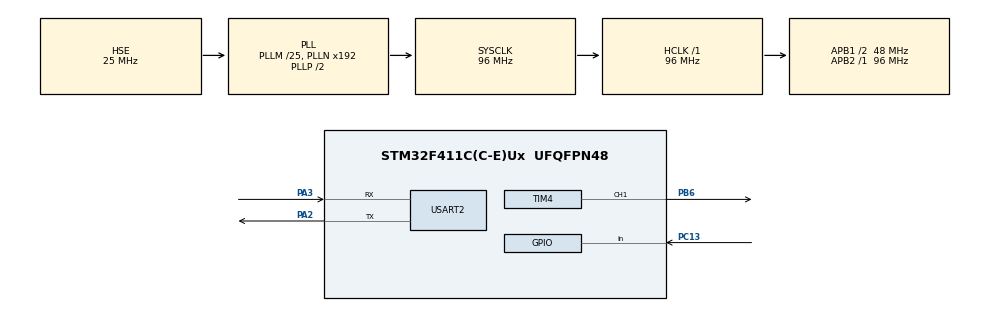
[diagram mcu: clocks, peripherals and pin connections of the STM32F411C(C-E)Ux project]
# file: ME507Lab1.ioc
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Mcu.Family=STM32F4
Mcu.Name=STM32F411C(C-E)Ux
Mcu.Package=UFQFPN48
NVIC.PriorityGroup=NVIC_PRIORITYGROUP_4
NVIC.TIM4_IRQn=true\:0\:0\:false\:false\:true\:true\:true\:true
PA13.Mode=Trace_Asynchronous_SW
PA13.Signal=SYS_JTMS-SWDIO
PA14.Mode=Trace_Asynchronous_SW
PA14.Signal=SYS_JTCK-SWCLK
PA2.Mode=Asynchronous
PA2.Signal=USART2_TX
PA3.Mode=Asynchronous
PA3.Signal=USART2_RX
PB3.Mode=Trace_Asynchronous_SW
PB3.Signal=SYS_JTDO-SWO
PB6.Signal=S_TIM4_CH1
PC13-ANTI_TAMP.Signal=GPIO_Input
PH0\ -\ OSC_IN.Mode=HSE-External-Oscillator
PH0\ -\ OSC_IN.Signal=RCC_OSC_IN
PH1\ -\ OSC_OUT.Mode=HSE-External-Oscillator
PH1\ -\ OSC_OUT.Signal=RCC_OSC_OUT
ProjectManager.HeapSize=0x200
ProjectManager.StackSize=0x400
ProjectManager.TargetToolchain=STM32CubeIDE
RCC.48MHZClocksFreq_Value=48000000
RCC.AHBFreq_Value=96000000
RCC.APB1CLKDivider=RCC_HCLK_DIV2
RCC.APB1Freq_Value=48000000
RCC.APB1TimFreq_Value=96000000
RCC.APB2Freq_Value=96000000
RCC.APB2TimFreq_Value=96000000
RCC.CortexFreq_Value=96000000
RCC.HCLKFreq_Value=96000000
RCC.HSE_VALUE=25000000
RCC.HSI_VALUE=16000000
RCC.LSE_VALUE=32768
RCC.PLLM=25
RCC.PLLSourceVirtual=RCC_PLLSOURCE_HSE
RCC.SYSCLKFreq_VALUE=96000000
RCC.SYSCLKSource=RCC_SYSCLKSOURCE_PLLCLK
RCC.VCOOutputFreq_Value=192000000
SH.S_TIM4_CH1.0=TIM4_CH1,PWM Generation1 CH1
TIM4.Channel-PWM\ Generation1\ CH1=TIM_CHANNEL_1
TIM4.OCPolarity_1=TIM_OCPOLARITY_LOW
TIM4.Period=63999
TIM4.Prescaler=749
TIM4.Pulse-PWM\ Generation1\ CH1=25600
TIM4.TIM_MasterOutputTrigger=TIM_TRGO_OC1
USART2.VirtualMode=VM_ASYNC
VP_TIM5_VS_ClockSourceITR.Mode=TriggerSource_ITR2
VP_TIM5_VS_ControllerModeClock.Mode=Clock Mode
board=custom

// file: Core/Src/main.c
/* USER CODE BEGIN Header */
/**
  ******************************************************************************
  * @file           : main.c
  * @brief          : Main program body
  ******************************************************************************
  * @attention
  *
  * Copyright (c) 2026 STMicroelectronics.
  * All rights reserved.
  *
  * This software is licensed under terms that can be found in the LICENSE file
  * in the root directory of this software component.
  * If no LICENSE file comes with this software, it is provided AS-IS.
  *
  ******************************************************************************
  */
/* USER CODE END Header */
#include "main.h"

/* USER CODE BEGIN Includes */
#include <stdio.h>
/* USER CODE END Includes */

TIM_HandleTypeDef htim4;
TIM_HandleTypeDef htim5;

UART_HandleTypeDef huart2;

/* USER CODE BEGIN PV */
uint16_t pulse_width = 25600;
char buffer [100];
int buffer_len;
/* USER CODE END PV */

void SystemClock_Config(void);
static void MX_GPIO_Init(void);
static void MX_USART2_UART_Init(void);
static void MX_TIM4_Init(void);
static void MX_TIM5_Init(void);

int main(void)
{

  /* MCU Configuration--------------------------------------------------------*/

  /* Reset of all peripherals, Initializes the Flash interface and the Systick. */
  HAL_Init();

  /* Configure the system clock */
  SystemClock_Config();

  /* Initialize all configured peripherals */
  MX_GPIO_Init();
  MX_USART2_UART_Init();
  MX_TIM4_Init();
  MX_TIM5_Init();
  /* USER CODE BEGIN 2 */
  HAL_TIM_PWM_Start_IT(&htim4, TIM_CHANNEL_1);
  HAL_TIM_Base_Start(&htim5);
  /* USER CODE END 2 */

  /* Infinite loop */
  /* USER CODE BEGIN WHILE */
  while (1)
  {
	__HAL_TIM_SET_COMPARE(&htim4, TIM_CHANNEL_1, pulse_width); // Update Duty Cycle
	HAL_Delay(100);
    /* USER CODE END WHILE */

  }
}

void SystemClock_Config(void)
{
  RCC_OscInitTypeDef RCC_OscInitStruct = {0};
  RCC_ClkInitTypeDef RCC_ClkInitStruct = {0};

  /** Configure the main internal regulator output voltage
  */
  __HAL_RCC_PWR_CLK_ENABLE();
  __HAL_PWR_VOLTAGESCALING_CONFIG(PWR_REGULATOR_VOLTAGE_SCALE1);

  /** Initializes the RCC Oscillators according to the specified parameters
  * in the RCC_OscInitTypeDef structure.
  */
  RCC_OscInitStruct.OscillatorType = RCC_OSCILLATORTYPE_HSE;
  RCC_OscInitStruct.HSEState = RCC_HSE_ON;
  RCC_OscInitStruct.PLL.PLLState = RCC_PLL_ON;
  RCC_OscInitStruct.PLL.PLLSource = RCC_PLLSOURCE_HSE;
  RCC_OscInitStruct.PLL.PLLM = 25;
  RCC_OscInitStruct.PLL.PLLN = 192;
  RCC_OscInitStruct.PLL.PLLP = RCC_PLLP_DIV2;
  RCC_OscInitStruct.PLL.PLLQ = 4;
  if (HAL_RCC_OscConfig(&RCC_OscInitStruct) != HAL_OK)
  {
    Error_Handler();
  }

  /** Initializes the CPU, AHB and APB buses clocks
  */
  RCC_ClkInitStruct.ClockType = RCC_CLOCKTYPE_HCLK|RCC_CLOCKTYPE_SYSCLK
                              |RCC_CLOCKTYPE_PCLK1|RCC_CLOCKTYPE_PCLK2;
  RCC_ClkInitStruct.SYSCLKSource = RCC_SYSCLKSOURCE_PLLCLK;
  RCC_ClkInitStruct.AHBCLKDivider = RCC_SYSCLK_DIV1;
  RCC_ClkInitStruct.APB1CLKDivider = RCC_HCLK_DIV2;
  RCC_ClkInitStruct.APB2CLKDivider = RCC_HCLK_DIV1;

  if (HAL_RCC_ClockConfig(&RCC_ClkInitStruct, FLASH_LATENCY_3) != HAL_OK)
  {
    Error_Handler();
  }
}

static void MX_TIM4_Init(void)
{

  TIM_MasterConfigTypeDef sMasterConfig = {0};
  TIM_OC_InitTypeDef sConfigOC = {0};

  htim4.Instance = TIM4;
  htim4.Init.Prescaler = 749;
  htim4.Init.CounterMode = TIM_COUNTERMODE_UP;
  htim4.Init.Period = 63999;
  htim4.Init.ClockDivision = TIM_CLOCKDIVISION_DIV1;
  htim4.Init.AutoReloadPreload = TIM_AUTORELOAD_PRELOAD_DISABLE;
  if (HAL_TIM_PWM_Init(&htim4) != HAL_OK)
  {
    Error_Handler();
  }
  sMasterConfig.MasterOutputTrigger = TIM_TRGO_OC1;
  sMasterConfig.MasterSlaveMode = TIM_MASTERSLAVEMODE_DISABLE;
  if (HAL_TIMEx_MasterConfigSynchronization(&htim4, &sMasterConfig) != HAL_OK)
  {
    Error_Handler();
  }
  sConfigOC.OCMode = TIM_OCMODE_PWM1;
  sConfigOC.Pulse = 25600;
  sConfigOC.OCPolarity = TIM_OCPOLARITY_LOW;
  sConfigOC.OCFastMode = TIM_OCFAST_DISABLE;
  if (HAL_TIM_PWM_ConfigChannel(&htim4, &sConfigOC, TIM_CHANNEL_1) != HAL_OK)
  {
    Error_Handler();
  }
  HAL_TIM_MspPostInit(&htim4);

}

static void MX_TIM5_Init(void)
{

  TIM_SlaveConfigTypeDef sSlaveConfig = {0};
  TIM_MasterConfigTypeDef sMasterConfig = {0};

  htim5.Instance = TIM5;
  htim5.Init.Prescaler = 0;
  htim5.Init.CounterMode = TIM_COUNTERMODE_UP;
  htim5.Init.Period = 4294967295;
  htim5.Init.ClockDivision = TIM_CLOCKDIVISION_DIV1;
  htim5.Init.AutoReloadPreload = TIM_AUTORELOAD_PRELOAD_DISABLE;
  if (HAL_TIM_Base_Init(&htim5) != HAL_OK)
  {
    Error_Handler();
  }
  sSlaveConfig.SlaveMode = TIM_SLAVEMODE_EXTERNAL1;
  sSlaveConfig.InputTrigger = TIM_TS_ITR2;
  if (HAL_TIM_SlaveConfigSynchro(&htim5, &sSlaveConfig) != HAL_OK)
  {
    Error_Handler();
  }
  sMasterConfig.MasterOutputTrigger = TIM_TRGO_RESET;
  sMasterConfig.MasterSlaveMode = TIM_MASTERSLAVEMODE_DISABLE;
  if (HAL_TIMEx_MasterConfigSynchronization(&htim5, &sMasterConfig) != HAL_OK)
  {
    Error_Handler();
  }

}

static void MX_USART2_UART_Init(void)
{

  huart2.Instance = USART2;
  huart2.Init.BaudRate = 115200;
  huart2.Init.WordLength = UART_WORDLENGTH_8B;
  huart2.Init.StopBits = UART_STOPBITS_1;
  huart2.Init.Parity = UART_PARITY_NONE;
  huart2.Init.Mode = UART_MODE_TX_RX;
  huart2.Init.HwFlowCtl = UART_HWCONTROL_NONE;
  huart2.Init.OverSampling = UART_OVERSAMPLING_16;
  if (HAL_UART_Init(&huart2) != HAL_OK)
  {
    Error_Handler();
  }

}

static void MX_GPIO_Init(void)
{
  GPIO_InitTypeDef GPIO_InitStruct = {0};

  /* GPIO Ports Clock Enable */
  __HAL_RCC_GPIOC_CLK_ENABLE();
  __HAL_RCC_GPIOH_CLK_ENABLE();
  __HAL_RCC_GPIOA_CLK_ENABLE();
  __HAL_RCC_GPIOB_CLK_ENABLE();

  /*Configure GPIO pin : PC13 */
  GPIO_InitStruct.Pin = GPIO_PIN_13;
  GPIO_InitStruct.Mode = GPIO_MODE_INPUT;
  GPIO_InitStruct.Pull = GPIO_NOPULL;
  HAL_GPIO_Init(GPIOC, &GPIO_InitStruct);

}

/* USER CODE BEGIN 4 */
void HAL_TIM_PWM_PulseFinishedCallback(TIM_HandleTypeDef *htim)
{
	buffer_len = snprintf(buffer, 100, "LED HAS BLINKED %d TIMES\n\r", __HAL_TIM_GET_COUNTER(&htim5));
	HAL_UART_Transmit(&huart2, buffer, buffer_len, 100);
}
/* USER CODE END 4 */

void Error_Handler(void)
{
  __disable_irq();
  while (1)
  {
  }
}
